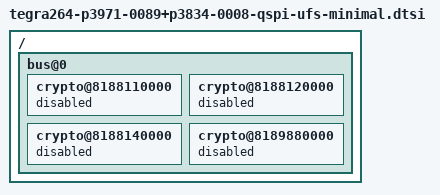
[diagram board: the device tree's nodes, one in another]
// SPDX-License-Identifier: GPL-2.0-only
// SPDX-FileCopyrightText: Copyright (c) 2024, NVIDIA CORPORATION & AFFILIATES.  All rights reserved.

/ {
	bus@0 {
		crypto@8188110000 {
			status = "disabled";
		};

		crypto@8188120000 {
			status = "disabled";
		};

		crypto@8188140000 {
			status = "disabled";
		};

		crypto@8189880000 {
			status = "disabled";
		};
	};
};
